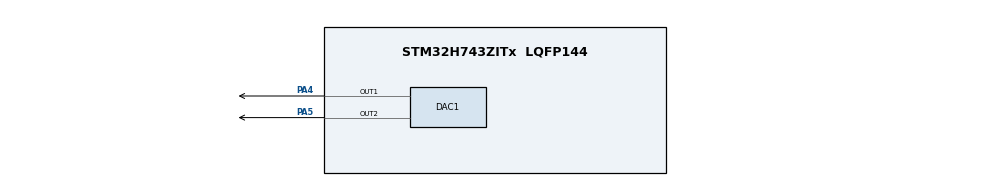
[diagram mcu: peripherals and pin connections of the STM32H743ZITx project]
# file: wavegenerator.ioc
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CORTEX_M7.default_mode_Activation=1
DAC1.DAC_Channel-DAC_OUT1=DAC_CHANNEL_1
DAC1.DAC_Channel-DAC_OUT2=DAC_CHANNEL_2
DAC1.DAC_Trigger-DAC_OUT1=DAC_TRIGGER_T1_TRGO
Dma.DAC1_CH1.0.Direction=DMA_MEMORY_TO_PERIPH
Dma.DAC1_CH1.0.EventEnable=DISABLE
Dma.DAC1_CH1.0.FIFOMode=DMA_FIFOMODE_DISABLE
Dma.DAC1_CH1.0.Instance=DMA1_Stream0
Dma.DAC1_CH1.0.MemDataAlignment=DMA_MDATAALIGN_HALFWORD
Dma.DAC1_CH1.0.MemInc=DMA_MINC_ENABLE
Dma.DAC1_CH1.0.Mode=DMA_CIRCULAR
Dma.DAC1_CH1.0.PeriphDataAlignment=DMA_PDATAALIGN_HALFWORD
Dma.DAC1_CH1.0.PeriphInc=DMA_PINC_DISABLE
Dma.DAC1_CH1.0.Polarity=HAL_DMAMUX_REQ_GEN_RISING
Dma.DAC1_CH1.0.Priority=DMA_PRIORITY_HIGH
Dma.DAC1_CH1.0.RequestNumber=1
Dma.DAC1_CH1.0.SignalID=NONE
Dma.DAC1_CH1.0.SyncEnable=DISABLE
Dma.DAC1_CH1.0.SyncPolarity=HAL_DMAMUX_SYNC_NO_EVENT
Dma.DAC1_CH1.0.SyncRequestNumber=1
Dma.DAC1_CH1.0.SyncSignalID=NONE
Dma.Request0=DAC1_CH1
Mcu.Family=STM32H7
Mcu.Name=STM32H743ZITx
Mcu.Package=LQFP144
NVIC.DMA1_Stream0_IRQn=true\:0\:0\:false\:false\:true\:false\:true\:true
NVIC.PriorityGroup=NVIC_PRIORITYGROUP_4
PA4.Signal=COMP_DAC11_group
PA5.Signal=COMP_DAC12_group
ProjectManager.HeapSize=0x200
ProjectManager.StackSize=0x400
ProjectManager.TargetToolchain=CMake
RCC.ADCFreq_Value=129000000
RCC.APB1Freq_Value=100000000
RCC.APB2Freq_Value=100000000
RCC.APB3Freq_Value=100000000
RCC.APB4Freq_Value=100000000
RCC.CortexFreq_Value=400000000
RCC.D1PPRE=RCC_APB3_DIV2
RCC.D2PPRE1=RCC_APB1_DIV2
RCC.D2PPRE2=RCC_APB2_DIV2
RCC.D3PPRE=RCC_APB4_DIV2
RCC.DIVM1=4
RCC.DIVN1=50
RCC.HCLKFreq_Value=200000000
RCC.HPRE=RCC_HCLK_DIV2
RCC.PLLFRACN=0
RCC.SYSCLKFreq_VALUE=400000000
RCC.SYSCLKSource=RCC_SYSCLKSOURCE_PLLCLK
RCC.USBFreq_Value=400000000
SH.COMP_DAC11_group.0=DAC1_OUT1,DAC_OUT1
SH.COMP_DAC12_group.0=DAC1_OUT2,DAC_OUT2
TIM1.Period=19999
TIM1.TIM_MasterOutputTrigger=TIM_TRGO_UPDATE
VP_MEMORYMAP_VS_MEMORYMAP.Mode=CurAppReg
VP_TIM1_VS_ClockSourceINT.Mode=Internal
board=custom

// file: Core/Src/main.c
/* USER CODE BEGIN Header */
/**
  ******************************************************************************
  * @file           : main.c
  * @brief          : Main program body
  ******************************************************************************
  * @attention
  *
  * Copyright (c) 2026 STMicroelectronics.
  * All rights reserved.
  *
  * This software is licensed under terms that can be found in the LICENSE file
  * in the root directory of this software component.
  * If no LICENSE file comes with this software, it is provided AS-IS.
  *
  ******************************************************************************
  */
/* USER CODE END Header */
#include "main.h"

/* USER CODE BEGIN Includes */
#include <string.h>
#include <math.h>
/* USER CODE END Includes */

/* USER CODE BEGIN PD */
#define SINE_POINTS 128
/* USER CODE END PD */

DAC_HandleTypeDef hdac1;
DMA_HandleTypeDef hdma_dac1_ch1;

TIM_HandleTypeDef htim1;

/* USER CODE BEGIN PV */
#define SINE_POINTS 128

// 加上 const 固化在 Flash，彻底规避 H7 的 Cache 一致性问题
const uint16_t sine_table[SINE_POINTS] = {
    2048, 2447, 2831, 3185, 3495, 3750, 3939, 4056,
    4095, 4056, 3939, 3750, 3495, 3185, 2831, 2447,
    2048, 1648, 1264,  910,  600,  345,  156,   39,
       0,   39,  156,  345,  600,  910, 1264, 1648
};

volatile uint32_t g_dac_sr   = 0;
volatile uint32_t g_dac_cr   = 0;
volatile uint32_t g_dma_lisr = 0;
volatile uint32_t g_dma_ndtr = 0;

/* USER CODE END PV */

void SystemClock_Config(void);
static void MPU_Config(void);
static void MX_GPIO_Init(void);
static void MX_DMA_Init(void);
static void MX_DAC1_Init(void);
static void MX_TIM1_Init(void);

int main(void)
{

  /* MPU Configuration--------------------------------------------------------*/
  MPU_Config();

  /* MCU Configuration--------------------------------------------------------*/

  /* Reset of all peripherals, Initializes the Flash interface and the Systick. */
  HAL_Init();

  /* Configure the system clock */
  SystemClock_Config();

  /* Initialize all configured peripherals */
  MX_GPIO_Init();
  MX_DMA_Init();
  MX_DAC1_Init();
  MX_TIM1_Init();
  /* USER CODE BEGIN 2 */
  __HAL_RCC_D2SRAM1_CLK_ENABLE();
  uint16_t *dac_dma_buf = (uint16_t *)0x30000000;

  // 将直流偏置降至 1800，振幅降至 500（峰值 2300，谷值 1300）
  for (int i = 0; i < SINE_POINTS; i++) {
    dac_dma_buf[i] = (uint16_t)(1800.0f + 500.0f * sinf(2.0f * 3.14159265f * (float)i / (float)SINE_POINTS));
  }

  HAL_DAC_Start_DMA(&hdac1, DAC_CHANNEL_1, (uint32_t *)dac_dma_buf, SINE_POINTS, DAC_ALIGN_12B_R);
  // 2. 启动 DMA 循环传输

  // 3. 将 TIM1 (或 TIM6) 的 Period (ARR) 设为 120 左右，使正弦波频率达到约 13 kHz
  // htim1.Init.Period = 120; // 200MHz / 121 / 128 ≈ 12.9 kHz (屏幕约呈现 2 个完整周期)
  HAL_TIM_Base_Start(&htim1);
  /* USER CODE END 2 */

  /* Infinite loop */
  while (1)
  {

  }
}

void SystemClock_Config(void)
{
  RCC_OscInitTypeDef RCC_OscInitStruct = {0};
  RCC_ClkInitTypeDef RCC_ClkInitStruct = {0};

  /** Supply configuration update enable
  */
  HAL_PWREx_ConfigSupply(PWR_LDO_SUPPLY);

  /** Configure the main internal regulator output voltage
  */
  __HAL_PWR_VOLTAGESCALING_CONFIG(PWR_REGULATOR_VOLTAGE_SCALE1);

  while(!__HAL_PWR_GET_FLAG(PWR_FLAG_VOSRDY)) {}

  /** Initializes the RCC Oscillators according to the specified parameters
  * in the RCC_OscInitTypeDef structure.
  */
  RCC_OscInitStruct.OscillatorType = RCC_OSCILLATORTYPE_HSI;
  RCC_OscInitStruct.HSIState = RCC_HSI_DIV1;
  RCC_OscInitStruct.HSICalibrationValue = RCC_HSICALIBRATION_DEFAULT;
  RCC_OscInitStruct.PLL.PLLState = RCC_PLL_ON;
  RCC_OscInitStruct.PLL.PLLSource = RCC_PLLSOURCE_HSI;
  RCC_OscInitStruct.PLL.PLLM = 4;
  RCC_OscInitStruct.PLL.PLLN = 50;
  RCC_OscInitStruct.PLL.PLLP = 2;
  RCC_OscInitStruct.PLL.PLLQ = 2;
  RCC_OscInitStruct.PLL.PLLR = 2;
  RCC_OscInitStruct.PLL.PLLRGE = RCC_PLL1VCIRANGE_3;
  RCC_OscInitStruct.PLL.PLLVCOSEL = RCC_PLL1VCOWIDE;
  RCC_OscInitStruct.PLL.PLLFRACN = 0;
  if (HAL_RCC_OscConfig(&RCC_OscInitStruct) != HAL_OK)
  {
    Error_Handler();
  }

  /** Initializes the CPU, AHB and APB buses clocks
  */
  RCC_ClkInitStruct.ClockType = RCC_CLOCKTYPE_HCLK|RCC_CLOCKTYPE_SYSCLK
                              |RCC_CLOCKTYPE_PCLK1|RCC_CLOCKTYPE_PCLK2
                              |RCC_CLOCKTYPE_D3PCLK1|RCC_CLOCKTYPE_D1PCLK1;
  RCC_ClkInitStruct.SYSCLKSource = RCC_SYSCLKSOURCE_PLLCLK;
  RCC_ClkInitStruct.SYSCLKDivider = RCC_SYSCLK_DIV1;
  RCC_ClkInitStruct.AHBCLKDivider = RCC_HCLK_DIV2;
  RCC_ClkInitStruct.APB3CLKDivider = RCC_APB3_DIV2;
  RCC_ClkInitStruct.APB1CLKDivider = RCC_APB1_DIV2;
  RCC_ClkInitStruct.APB2CLKDivider = RCC_APB2_DIV2;
  RCC_ClkInitStruct.APB4CLKDivider = RCC_APB4_DIV2;

  if (HAL_RCC_ClockConfig(&RCC_ClkInitStruct, FLASH_LATENCY_2) != HAL_OK)
  {
    Error_Handler();
  }
}

static void MX_DAC1_Init(void)
{

  DAC_ChannelConfTypeDef sConfig = {0};

  /** DAC Initialization
  */
  hdac1.Instance = DAC1;
  if (HAL_DAC_Init(&hdac1) != HAL_OK)
  {
    Error_Handler();
  }

  /** DAC channel OUT1 config
  */
  sConfig.DAC_SampleAndHold = DAC_SAMPLEANDHOLD_DISABLE;
  sConfig.DAC_Trigger = DAC_TRIGGER_T1_TRGO;
  sConfig.DAC_OutputBuffer = DAC_OUTPUTBUFFER_ENABLE;
  sConfig.DAC_ConnectOnChipPeripheral = DAC_CHIPCONNECT_DISABLE;
  sConfig.DAC_UserTrimming = DAC_TRIMMING_FACTORY;
  if (HAL_DAC_ConfigChannel(&hdac1, &sConfig, DAC_CHANNEL_1) != HAL_OK)
  {
    Error_Handler();
  }

  /** DAC channel OUT2 config
  */
  sConfig.DAC_Trigger = DAC_TRIGGER_NONE;
  if (HAL_DAC_ConfigChannel(&hdac1, &sConfig, DAC_CHANNEL_2) != HAL_OK)
  {
    Error_Handler();
  }

}

static void MX_TIM1_Init(void)
{

  TIM_ClockConfigTypeDef sClockSourceConfig = {0};
  TIM_MasterConfigTypeDef sMasterConfig = {0};

  htim1.Instance = TIM1;
  htim1.Init.Prescaler = 0;
  htim1.Init.CounterMode = TIM_COUNTERMODE_UP;
  htim1.Init.Period = 156;
  htim1.Init.ClockDivision = TIM_CLOCKDIVISION_DIV1;
  htim1.Init.RepetitionCounter = 0;
  htim1.Init.AutoReloadPreload = TIM_AUTORELOAD_PRELOAD_DISABLE;
  if (HAL_TIM_Base_Init(&htim1) != HAL_OK)
  {
    Error_Handler();
  }
  sClockSourceConfig.ClockSource = TIM_CLOCKSOURCE_INTERNAL;
  if (HAL_TIM_ConfigClockSource(&htim1, &sClockSourceConfig) != HAL_OK)
  {
    Error_Handler();
  }
  sMasterConfig.MasterOutputTrigger = TIM_TRGO_UPDATE;
  sMasterConfig.MasterOutputTrigger2 = TIM_TRGO2_RESET;
  sMasterConfig.MasterSlaveMode = TIM_MASTERSLAVEMODE_DISABLE;
  if (HAL_TIMEx_MasterConfigSynchronization(&htim1, &sMasterConfig) != HAL_OK)
  {
    Error_Handler();
  }

}

static void MX_DMA_Init(void)
{

  /* DMA controller clock enable */
  __HAL_RCC_DMA1_CLK_ENABLE();

  /* DMA interrupt init */
  /* DMA1_Stream0_IRQn interrupt configuration */
  HAL_NVIC_SetPriority(DMA1_Stream0_IRQn, 0, 0);
  HAL_NVIC_EnableIRQ(DMA1_Stream0_IRQn);

}

static void MX_GPIO_Init(void)
{

  /* GPIO Ports Clock Enable */
  __HAL_RCC_GPIOA_CLK_ENABLE();

}

 /* MPU Configuration */

void MPU_Config(void)
{
  MPU_Region_InitTypeDef MPU_InitStruct = {0};

  /* Disables the MPU */
  HAL_MPU_Disable();

  /** Initializes and configures the Region and the memory to be protected
  */
  MPU_InitStruct.Enable = MPU_REGION_ENABLE;
  MPU_InitStruct.Number = MPU_REGION_NUMBER0;
  MPU_InitStruct.BaseAddress = 0x0;
  MPU_InitStruct.Size = MPU_REGION_SIZE_4GB;
  MPU_InitStruct.SubRegionDisable = 0x87;
  MPU_InitStruct.TypeExtField = MPU_TEX_LEVEL0;
  MPU_InitStruct.AccessPermission = MPU_REGION_NO_ACCESS;
  MPU_InitStruct.DisableExec = MPU_INSTRUCTION_ACCESS_DISABLE;
  MPU_InitStruct.IsShareable = MPU_ACCESS_SHAREABLE;
  MPU_InitStruct.IsCacheable = MPU_ACCESS_NOT_CACHEABLE;
  MPU_InitStruct.IsBufferable = MPU_ACCESS_NOT_BUFFERABLE;

  HAL_MPU_ConfigRegion(&MPU_InitStruct);
  /* Enables the MPU */
  HAL_MPU_Enable(MPU_PRIVILEGED_DEFAULT);

}

void Error_Handler(void)
{
  __disable_irq();
  while (1)
  {
  }
}
